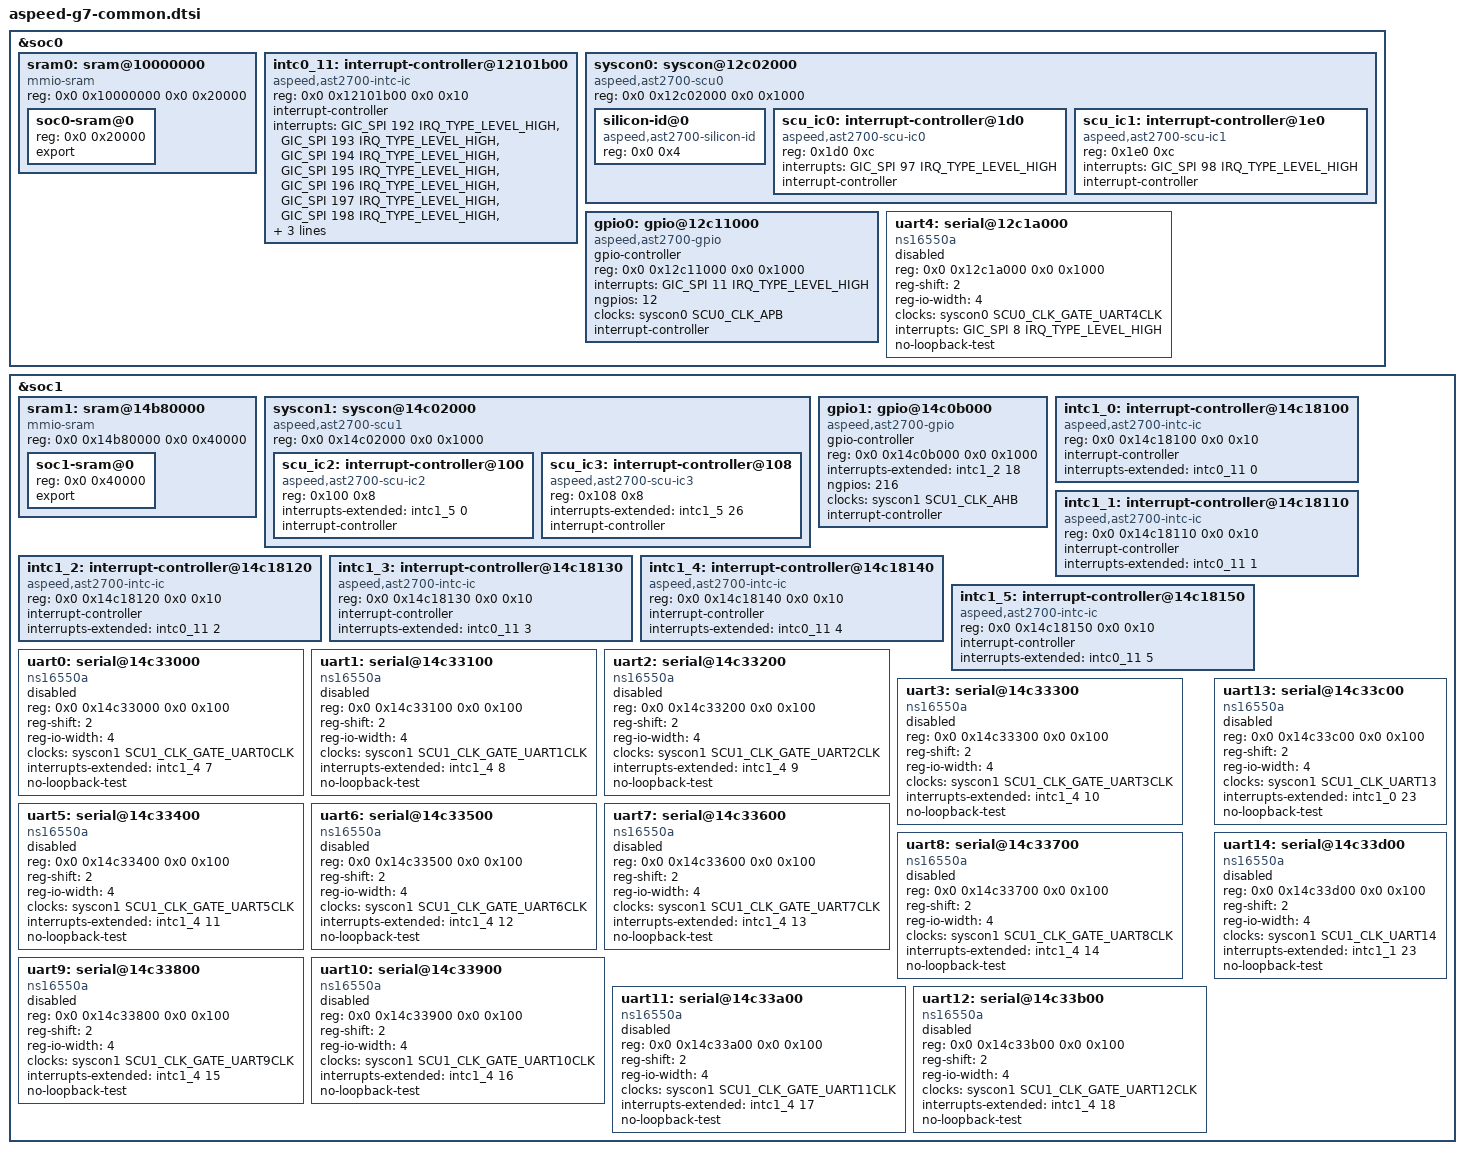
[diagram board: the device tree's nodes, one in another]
// SPDX-License-Identifier: GPL-2.0-or-later
#include <dt-bindings/clock/aspeed,ast2700-scu.h>
#include <dt-bindings/reset/aspeed,ast2700-scu.h>
#include <dt-bindings/interrupt-controller/aspeed-scu-ic.h>

&soc0 {
	sram0: sram@10000000 {
		compatible = "mmio-sram";
		reg = <0x0 0x10000000 0x0 0x20000>;
		ranges = <0x0 0x0 0x10000000 0x20000>;
		#address-cells = <1>;
		#size-cells = <1>;

		soc0-sram@0 {
			reg = <0x0 0x20000>;
			export;
		};
	};

	intc0_11: interrupt-controller@12101b00 {
		compatible = "aspeed,ast2700-intc-ic";
		reg = <0x0 0x12101b00 0x0 0x10>;
		#interrupt-cells = <1>;
		interrupt-controller;
		interrupts = <GIC_SPI 192 IRQ_TYPE_LEVEL_HIGH>,
				<GIC_SPI 193 IRQ_TYPE_LEVEL_HIGH>,
				<GIC_SPI 194 IRQ_TYPE_LEVEL_HIGH>,
				<GIC_SPI 195 IRQ_TYPE_LEVEL_HIGH>,
				<GIC_SPI 196 IRQ_TYPE_LEVEL_HIGH>,
				<GIC_SPI 197 IRQ_TYPE_LEVEL_HIGH>,
				<GIC_SPI 198 IRQ_TYPE_LEVEL_HIGH>,
				<GIC_SPI 199 IRQ_TYPE_LEVEL_HIGH>,
				<GIC_SPI 200 IRQ_TYPE_LEVEL_HIGH>,
				<GIC_SPI 201 IRQ_TYPE_LEVEL_HIGH>;
	};

	syscon0: syscon@12c02000 {
		compatible = "aspeed,ast2700-scu0", "syscon", "simple-mfd";
		reg = <0x0 0x12c02000 0x0 0x1000>;
		ranges = <0x0 0x0 0x12c02000 0x1000>;
		#address-cells = <1>;
		#size-cells = <1>;
		#clock-cells = <1>;
		#reset-cells = <1>;

		silicon-id@0 {
			compatible = "aspeed,ast2700-silicon-id", "aspeed,silicon-id";
			reg = <0x0 0x4>;
		};

		scu_ic0: interrupt-controller@1d0 {
			compatible = "aspeed,ast2700-scu-ic0";
			reg = <0x1d0 0xc>;
			#interrupt-cells = <1>;
			interrupts = <GIC_SPI 97 IRQ_TYPE_LEVEL_HIGH>;
			interrupt-controller;
		};

		scu_ic1: interrupt-controller@1e0 {
			compatible = "aspeed,ast2700-scu-ic1";
			reg = <0x1e0 0xc>;
			#interrupt-cells = <1>;
			interrupts = <GIC_SPI 98 IRQ_TYPE_LEVEL_HIGH>;
			interrupt-controller;
		};
	};

	gpio0: gpio@12c11000 {
		#gpio-cells = <2>;
		gpio-controller;
		compatible = "aspeed,ast2700-gpio";
		reg = <0x0 0x12c11000 0x0 0x1000>;
		interrupts = <GIC_SPI 11 IRQ_TYPE_LEVEL_HIGH>;
		ngpios = <12>;
		clocks = <&syscon0 SCU0_CLK_APB>;
		interrupt-controller;
		#interrupt-cells = <2>;
	};

	uart4: serial@12c1a000 {
		compatible = "ns16550a";
		reg = <0x0 0x12c1a000 0x0 0x1000>;
		reg-shift = <2>;
		reg-io-width = <4>;
		clocks = <&syscon0 SCU0_CLK_GATE_UART4CLK>;
		interrupts = <GIC_SPI 8 IRQ_TYPE_LEVEL_HIGH>;
		no-loopback-test;
		status = "disabled";
	};
};

&soc1 {
	sram1: sram@14b80000 {
		compatible = "mmio-sram";
		reg = <0x0 0x14b80000 0x0 0x40000>;
		ranges = <0x0 0x0 0x14b80000 0x40000>;
		#address-cells = <1>;
		#size-cells = <1>;

		soc1-sram@0 {
			reg = <0x0 0x40000>;
			export;
		};
	};

	syscon1: syscon@14c02000 {
		compatible = "aspeed,ast2700-scu1", "syscon", "simple-mfd";
		reg = <0x0 0x14c02000 0x0 0x1000>;
		ranges = <0x0 0x0 0x14c02000 0x1000>;
		#address-cells = <1>;
		#size-cells = <1>;
		#clock-cells = <1>;
		#reset-cells = <1>;

		scu_ic2: interrupt-controller@100 {
			compatible = "aspeed,ast2700-scu-ic2";
			reg = <0x100 0x8>;
			#interrupt-cells = <1>;
			interrupts-extended = <&intc1_5 0>;
			interrupt-controller;
		};

		scu_ic3: interrupt-controller@108 {
			compatible = "aspeed,ast2700-scu-ic3";
			reg = <0x108 0x8>;
			#interrupt-cells = <1>;
			interrupts-extended = <&intc1_5 26>;
			interrupt-controller;
		};
	};

	gpio1: gpio@14c0b000 {
		#gpio-cells = <2>;
		gpio-controller;
		compatible = "aspeed,ast2700-gpio";
		reg = <0x0 0x14c0b000 0x0 0x1000>;
		interrupts-extended = <&intc1_2 18>;
		ngpios = <216>;
		clocks = <&syscon1 SCU1_CLK_AHB>;
		interrupt-controller;
		#interrupt-cells = <2>;
	};

	intc1_0: interrupt-controller@14c18100 {
		compatible = "aspeed,ast2700-intc-ic";
		reg = <0x0 0x14c18100 0x0 0x10>;
		#interrupt-cells = <1>;
		interrupt-controller;
		interrupts-extended = <&intc0_11 0>;
	};

	intc1_1: interrupt-controller@14c18110 {
		compatible = "aspeed,ast2700-intc-ic";
		reg = <0x0 0x14c18110 0x0 0x10>;
		#interrupt-cells = <1>;
		interrupt-controller;
		interrupts-extended = <&intc0_11 1>;
	};

	intc1_2: interrupt-controller@14c18120 {
		compatible = "aspeed,ast2700-intc-ic";
		reg = <0x0 0x14c18120 0x0 0x10>;
		#interrupt-cells = <1>;
		interrupt-controller;
		interrupts-extended = <&intc0_11 2>;
	};

	intc1_3: interrupt-controller@14c18130 {
		compatible = "aspeed,ast2700-intc-ic";
		reg = <0x0 0x14c18130 0x0 0x10>;
		#interrupt-cells = <1>;
		interrupt-controller;
		interrupts-extended = <&intc0_11 3>;
	};

	intc1_4: interrupt-controller@14c18140 {
		compatible = "aspeed,ast2700-intc-ic";
		reg = <0x0 0x14c18140 0x0 0x10>;
		#interrupt-cells = <1>;
		interrupt-controller;
		interrupts-extended = <&intc0_11 4>;
	};

	intc1_5: interrupt-controller@14c18150 {
		compatible = "aspeed,ast2700-intc-ic";
		reg = <0x0 0x14c18150 0x0 0x10>;
		#interrupt-cells = <1>;
		interrupt-controller;
		interrupts-extended = <&intc0_11 5>;
	};

	uart0: serial@14c33000 {
		compatible = "ns16550a";
		reg = <0x0 0x14c33000 0x0 0x100>;
		reg-shift = <2>;
		reg-io-width = <4>;
		clocks = <&syscon1 SCU1_CLK_GATE_UART0CLK>;
		interrupts-extended = <&intc1_4 7>;
		no-loopback-test;
		status = "disabled";
	};

	uart1: serial@14c33100 {
		compatible = "ns16550a";
		reg = <0x0 0x14c33100 0x0 0x100>;
		reg-shift = <2>;
		reg-io-width = <4>;
		clocks = <&syscon1 SCU1_CLK_GATE_UART1CLK>;
		interrupts-extended = <&intc1_4 8>;
		no-loopback-test;
		status = "disabled";
	};

	uart2: serial@14c33200 {
		compatible = "ns16550a";
		reg = <0x0 0x14c33200 0x0 0x100>;
		reg-shift = <2>;
		reg-io-width = <4>;
		clocks = <&syscon1 SCU1_CLK_GATE_UART2CLK>;
		interrupts-extended = <&intc1_4 9>;
		no-loopback-test;
		status = "disabled";
	};

	uart3: serial@14c33300 {
		compatible = "ns16550a";
		reg = <0x0 0x14c33300 0x0 0x100>;
		reg-shift = <2>;
		reg-io-width = <4>;
		clocks = <&syscon1 SCU1_CLK_GATE_UART3CLK>;
		interrupts-extended = <&intc1_4 10>;
		no-loopback-test;
		status = "disabled";
	};

	uart5: serial@14c33400 {
		compatible = "ns16550a";
		reg = <0x0 0x14c33400 0x0 0x100>;
		reg-shift = <2>;
		reg-io-width = <4>;
		clocks = <&syscon1 SCU1_CLK_GATE_UART5CLK>;
		interrupts-extended = <&intc1_4 11>;
		no-loopback-test;
		status = "disabled";
	};

	uart6: serial@14c33500 {
		compatible = "ns16550a";
		reg = <0x0 0x14c33500 0x0 0x100>;
		reg-shift = <2>;
		reg-io-width = <4>;
		clocks = <&syscon1 SCU1_CLK_GATE_UART6CLK>;
		interrupts-extended = <&intc1_4 12>;
		no-loopback-test;
		status = "disabled";
	};

	uart7: serial@14c33600 {
		compatible = "ns16550a";
		reg = <0x0 0x14c33600 0x0 0x100>;
		reg-shift = <2>;
		reg-io-width = <4>;
		clocks = <&syscon1 SCU1_CLK_GATE_UART7CLK>;
		interrupts-extended = <&intc1_4 13>;
		no-loopback-test;
		status = "disabled";
	};

	uart8: serial@14c33700 {
		compatible = "ns16550a";
		reg = <0x0 0x14c33700 0x0 0x100>;
		reg-shift = <2>;
		reg-io-width = <4>;
		clocks = <&syscon1 SCU1_CLK_GATE_UART8CLK>;
		interrupts-extended = <&intc1_4 14>;
		no-loopback-test;
		status = "disabled";
	};

	uart9: serial@14c33800 {
		compatible = "ns16550a";
		reg = <0x0 0x14c33800 0x0 0x100>;
		reg-shift = <2>;
		reg-io-width = <4>;
		clocks = <&syscon1 SCU1_CLK_GATE_UART9CLK>;
		interrupts-extended = <&intc1_4 15>;
		no-loopback-test;
		status = "disabled";
	};

	uart10: serial@14c33900 {
		compatible = "ns16550a";
		reg = <0x0 0x14c33900 0x0 0x100>;
		reg-shift = <2>;
		reg-io-width = <4>;
		clocks = <&syscon1 SCU1_CLK_GATE_UART10CLK>;
		interrupts-extended = <&intc1_4 16>;
		no-loopback-test;
		status = "disabled";
	};

	uart11: serial@14c33a00 {
		compatible = "ns16550a";
		reg = <0x0 0x14c33a00 0x0 0x100>;
		reg-shift = <2>;
		reg-io-width = <4>;
		clocks = <&syscon1 SCU1_CLK_GATE_UART11CLK>;
		interrupts-extended = <&intc1_4 17>;
		no-loopback-test;
		status = "disabled";
	};

	uart12: serial@14c33b00 {
		compatible = "ns16550a";
		reg = <0x0 0x14c33b00 0x0 0x100>;
		reg-shift = <2>;
		reg-io-width = <4>;
		clocks = <&syscon1 SCU1_CLK_GATE_UART12CLK>;
		interrupts-extended = <&intc1_4 18>;
		no-loopback-test;
		status = "disabled";
	};

	uart13: serial@14c33c00 {
		compatible = "ns16550a";
		reg = <0x0 0x14c33c00 0x0 0x100>;
		reg-shift = <2>;
		reg-io-width = <4>;
		clocks = <&syscon1 SCU1_CLK_UART13>;
		interrupts-extended = <&intc1_0 23>;
		no-loopback-test;
		status = "disabled";
	};

	uart14: serial@14c33d00 {
		compatible = "ns16550a";
		reg = <0x0 0x14c33d00 0x0 0x100>;
		reg-shift = <2>;
		reg-io-width = <4>;
		clocks = <&syscon1 SCU1_CLK_UART14>;
		interrupts-extended = <&intc1_1 23>;
		no-loopback-test;
		status = "disabled";
	};
};
